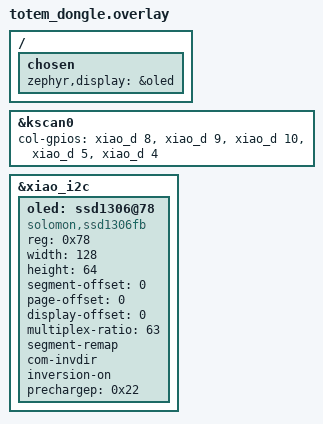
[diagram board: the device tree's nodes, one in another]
/*
 * Copyright (c) 2022 The ZMK Contributors
 *
 * SPDX-License-Identifier: MIT
 */

 #include "totem.dtsi"

/ {
    chosen {
        // zmk,kscan = &kscan0;
        zephyr,display = &oled;
    };
}

 &kscan0 {
     col-gpios
         = <&xiao_d 8 GPIO_ACTIVE_HIGH>
         , <&xiao_d 9 GPIO_ACTIVE_HIGH>
         , <&xiao_d 10 GPIO_ACTIVE_HIGH>
         , <&xiao_d 5 GPIO_ACTIVE_HIGH>
         , <&xiao_d 4 GPIO_ACTIVE_HIGH>
         ;
 };

&xiao_i2c {
    status = "okay";

    oled: ssd1306@78 {
        compatible = "solomon,ssd1306fb";
        reg = <0x78>;
        width = <128>;
        height = <64>;
        segment-offset = <0>;
        page-offset = <0>;
        display-offset = <0>;
        multiplex-ratio = <63>;
        segment-remap;
        com-invdir;
        inversion-on;
        prechargep = <0x22>;
    };
};
